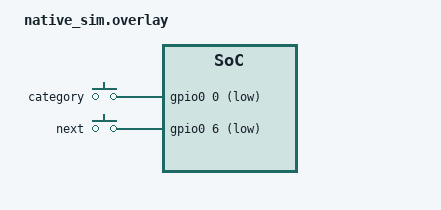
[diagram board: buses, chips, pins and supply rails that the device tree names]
/* Host build. */

#include <zephyr/dt-bindings/input/input-event-codes.h>

/ {
    aliases {
        cicala-category = &cicala_category;
        cicala-next = &cicala_next;
    };

    cicala_buttons: cicala-buttons {
        compatible = "gpio-keys";
        debounce-interval-ms = <30>;
        cicala_category: category {
            gpios = <&gpio0 0 GPIO_ACTIVE_LOW>;
            zephyr,code = <INPUT_KEY_MENU>;
            label = "category";
        };
        cicala_next: next {
            gpios = <&gpio0 6 GPIO_ACTIVE_LOW>;
            zephyr,code = <INPUT_KEY_ENTER>;
            label = "next";
        };
    };

    chosen {
        zephyr,display = &dummy_dc;
    };

    dummy_dc: dummy_dc {
        compatible = "zephyr,dummy-dc";
        width = <250>;
        height = <122>;
        status = "okay";
    };
};

/* native_sim's own devicetree enables an SDL display and chooses it. */
&sdl_dc {
    status = "disabled";
};
